# AC33Mx064 register map
Vendor: ABOV Semiconductor Co., Ltd.; File version: 0.1
CPU: CM3 r1p0, little endian, no MPU, no FPU, 3 interrupt priority bits
Registers are 32-bit, read-write, reset 0x0 unless marked. A register's access mark holds for its fields unless they carry their own. Offsets are from the block's base; [hi:lo] are bit positions; {n}, {i} and the like mark numbered series.

## PORTEN — Port Access Eable
Base 0x40001FF0
0x00 EN (reset mask 0xFFFF) — Port Access Eable 0x15->0x51

## PA — GENERAL PURPOSE I/O
Base 0x40002000
Same registers: PB 0x40002100, PC 0x40002200, PD 0x40002300
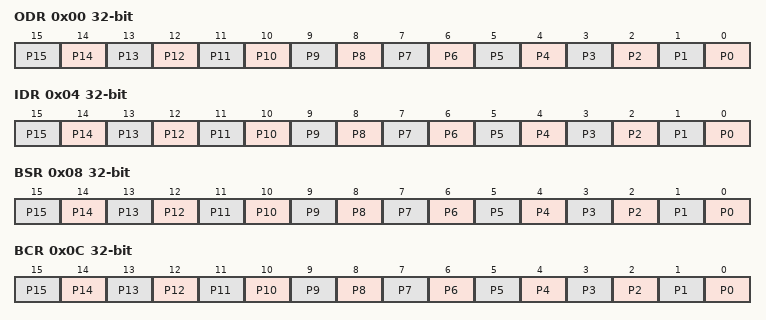
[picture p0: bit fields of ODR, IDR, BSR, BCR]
0x00 ODR — PORT n Output Data Register
  [n] P{n} (n=0..15) — P{n} Output level
0x04 IDR — PORT n Input Data Register
  [n] P{n} (n=0..15) — P{n} Input level
0x08 BSR — PORT n Bit Set Register
  [n] P{n} (n=0..15) — P{n} bit set
0x0C BCR wo — PORT n Bit Clear Register
  [n] P{n} (n=0..15) — P{n} bit clear

## FM — FLASH MEMORY CONTROLLER
Base 0x40000100
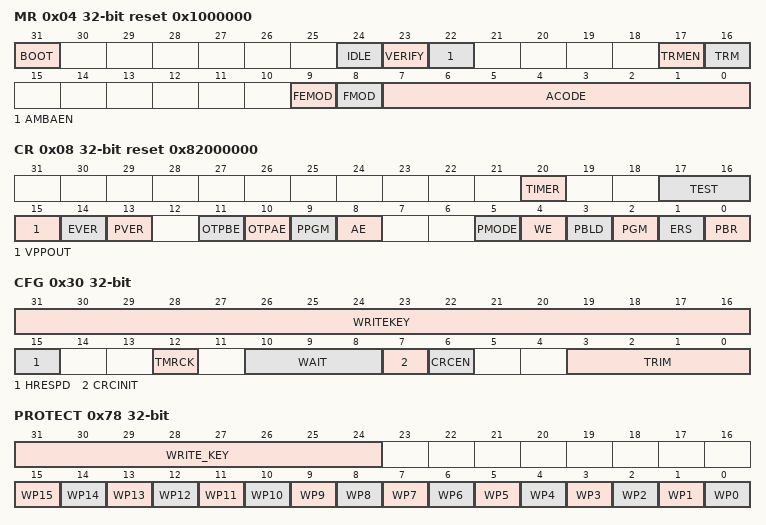
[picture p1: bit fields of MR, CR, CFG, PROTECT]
0x04 MR reset 0x1000000 — Flash Memory Mode Register
  [31] BOOT ro — Boot Mode enable status
  [24] IDLE ro — Idle mode enable status
  [23] VERIFY ro — Flash verify Mode enable status
  [22] AMBAEN — AMBA mode enable
  [17] TRMEN — Trim Mode entry status
  [16] TRM ro — Trim Mode status
  [9] FEMOD ro — Flash Mode entry status
  [8] FMOD ro — Flash Mode status
  [7:0] ACODE — Flash Mode/Trim Mode
0x08 CR reset 0x82000000 — Flash Memory Control Register
  [20] TIMER — program timer enable
  [17:16] TEST
  [15] VPPOUT ro — Charge pump Vpp Output
  [14] EVER — Erase verify Mode
  [13] PVER — Program verify mode
  [11] OTPBE — OTP area B enable
  [10] OTPAE — OTP area A enable
  [9] PPGM
  [8] AE — All Erase
  [5] PMODE — Pmode Enable
  [4] WE — write Enable
  [3] PBLD — page buffer load
  [2] PGM
  [1] ERS — program mode/erase mode Enable
  [0] PBR — page buffer reset
0x0C AR — Flash Memory Address Register
  [14:0] FADDR — 32K words address
0x10 DR — Flash Memory Data Register
  [31:0] FDATA — Flash PGM data
0x14 TMR reset 0x9C4 — Flash Memory Timer Register
  [8:0] TMR — Erase/PGM timer
0x18 DRTY — Flash Memory Dirty bit Register
  [31:0] FDRTY — Write any value,cache line fill falg will be cleared
0x1C TICK — Flash Memory Tick Timer register
  [17:0] FTICK — TICK
0x20 CRC — Flash Memory CRC value register
  [15:0] CRC — CRC16 Value
0x30 CFG — Flash Memory CONFIG value register
  [31:16] WRITEKEY
  [15] HRESPD
  [12] TMRCK
  [10:8] WAIT
  [7] CRCINIT
  [6] CRCEN — CRC16 Enable
  [3:0] TRIM
0x74 BOOTCR reset 0x1 — Boot ROM Remap Clear Register
  [0] BOOTROM — Boot mode
0x78 PROTECT — Write Protection Control Register
  [31:24] WRITE_KEY, [n] WP{n} (n=0..15)
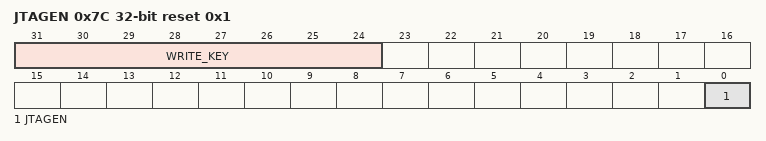
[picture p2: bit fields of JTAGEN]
0x7C JTAGEN reset 0x1 — JTAG Protection Control Register
  [31:24] WRITE_KEY, [0] JTAGEN

## DC0 — DIRECT MEMORY ACCESS CONTROLLER
Base 0x40000400
Same registers: DC1 0x40000410, DC2 0x40000420, DC3 0x40000430
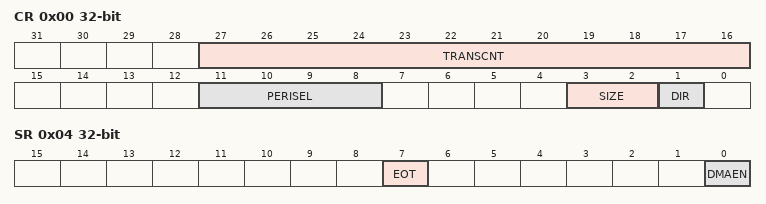
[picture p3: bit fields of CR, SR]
0x00 CR — DMA Controller Configuration Register
  [27:16] TRANSCNT — Numer of DMA transfer remained
  [11:8] PERISEL — eripheral selction
  [3:2] SIZE — Bus transfer size
  [1] DIR — Select transfer direction
0x04 SR — DMA Controller Status register
  [7] EOT ro — End of transfer
  [0] DMAEN — DMA enable
0x08 PAR — DMA Controller Peripheral Address register
0x0C MAR — DMA Controller Memory Address register
  [15:0] MAR — Memory address

## WDT — WATCH-DOG TIMER
Base 0x40000200
0x00 LR — Watchdog Timer Load Register
0x04 CNT reset 0xFFFF — Watchdog Timer Current Counter Register
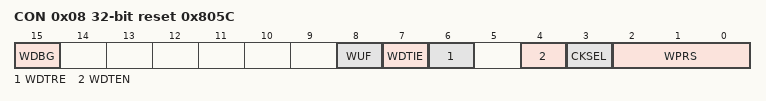
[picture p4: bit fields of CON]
0x08 CON reset 0x805C — Watchdog Timer Control Register
  [15] WDBG — WDT operation in debug mode
  [8] WUF — WDT underflow falg
  [7] WDTIE — WDT interrupt enable
  [6] WDTRE — WDT interrupt reset
  [4] WDTEN — WDT counter enable
  [3] CKSEL — WDTCLKIN clock source select
  [2:0] WPRS — counter prescaler

## T0 — 16-BIT TIMER
Base 0x40003000
Same registers: T1 0x40003020, T2 0x40003040, T3 0x40003060, T8 0x40003100, T9 0x40003120
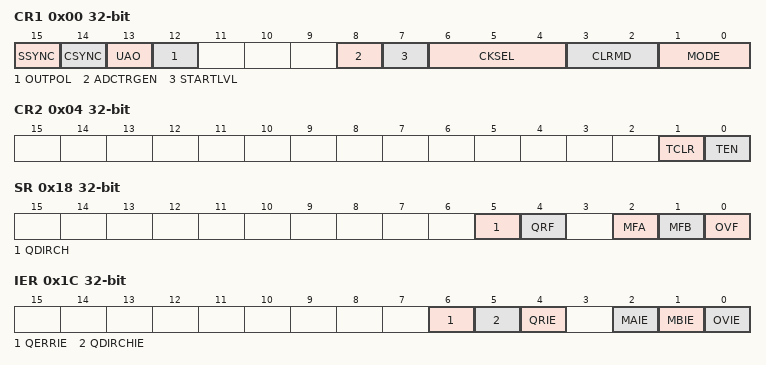
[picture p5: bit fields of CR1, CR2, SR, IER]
0x00 CR1 — Timer n Control Register 1
  [15] SSYNC
  [14] CSYNC
  [13] UAO
  [12] OUTPOL
  [8] ADCTRGEN
  [7] STARTLVL
  [6:4] CKSEL — counter clock source select
  [3:2] CLRMD — clear select when capture mode
  [1:0] MODE — Timer operatin mode control
0x04 CR2 — Timer n Control Register 2
  [1] TCLR — Timer register clear
  [0] TEN — Timer enable bit
0x08 PRS — Timer n Prescaler Register
  [9:0] PRS — Prescaler value of count clock
0x0C GRA — Timer n General Register A
  [15:0] GRA
0x10 GRB — Timer n General Register B
  [15:0] GRB
0x14 CNT — Timer n Count Register
  [15:0] CNT
0x18 SR — Timer n Status Register
  [5] QDIRCH — Quadrature direction change
  [4] QRF — Quadrature revolution flag
  [2] MFA — Match register A Flag
  [1] MFB — MATCH register B flag
  [0] OVF — counter overflow falg
0x1C IER wo — Timer n Interrupt Enable Register
  [6] QERRIE — Quadrature decoder error interrupt enable
  [5] QDIRCHIE — Quadrature direction change interrupt enable
  [4] QRIE — Quadrature revolution interrupt enable
  [2] MAIE — GRA Match interrupt enablee
  [1] MBIE — GRB Match interrupt enable
  [0] OVIE — Counter overflow interrupt enable
